# MDR1923VK014 register map
Vendor: Milandr; Series: ARMCM0; File version: 2.0
CPU: CM0 r0p0, little endian, no MPU, no FPU, 3 interrupt priority bits
Registers are 32-bit, read-write, reset 0x0 unless marked. A register's access mark holds for its fields unless they carry their own. Offsets are from the block's base; [hi:lo] are bit positions; {n}, {i} and the like mark numbered series; 'fields as' and 'values as' point back to an identical list.

## MDR_TIMER1 — TIMER Control
Base 0x4008A000
Same registers: MDR_TIMER2 0x4008B000, MDR_TIMER3 0x4008C000, MDR_TIMER4 0x4008D000, MDR_TIMER5 0x4008E000, MDR_TIMER6 0x4008F000
0x00 CNT — Counter register
  [31:0] Value — Counter Value
0x04 PSG — Presample Gain
  [15:0] Value — Inc CNT by PSG clocks of TIM_CLOCK
0x08 ARR — Counter Period
  [31:0] Value — Counter Value
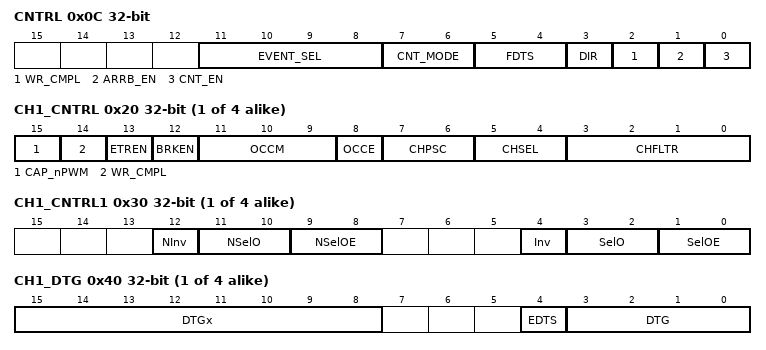
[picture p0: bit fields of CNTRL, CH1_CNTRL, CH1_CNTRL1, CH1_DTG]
0x0C CNTRL — Timer Control
  [11:8] EVENT_SEL — Events for counting
    0=Rise_TIM_CLK (CNT counts from 0 to ARR); 1=CNT_eq_ARR_TIM1 (CNT gets ARR in Timer1); 2=CNT_eq_ARR_TIM2 (CNT gets ARR in Timer2); 3=CNT_eq_ARR_TIM3 (CNT gets ARR in Timer3); {v}=Event_Ch{v-3} (Event in Channel{v-3}) (v=4..7); 8=Rise_ETR (Rise front in ETR pin); 9=Fall_ETR (Fall front in ETR pin); 10=CNT_eq_ARR_TIM4 (CNT gets ARR in Timer4)
  [7:6] CNT_MODE — Counting mode
    0=DIR_TIM_CLK (Count TIM_Clock pulses with DIR direction); 1=UpDown_TIM_CLK (Count TIM_Clock pulses UP and Down); 2=DIR_ExtEvents (Count External Events with DIR direction)
  [5:4] FDTS — Select Data Sampling frequency
    0=TIM_CLK_div1 (TIM_Clock to FDTS scale); 1=TIM_CLK_div2 (TIM_Clock to FDTS scale); 2=TIM_CLK_div4 (TIM_Clock to FDTS scale); 3=TIM_CLK_div8 (TIM_Clock to FDTS scale)
  [3] DIR — Count Direction
    0=UP (CNT counts from 0 to ARR); 1=DOWN (CNT counts from ARR to 0)
  [2] WR_CMPL — Can write to CNT, ARR, PSG
    0=Ready to write; 1=BUSY (Writing not completed)
  [1] ARRB_EN — ARR update mode
    0=Immediately update; 1=OnCompleted (Update ARR when active period of CNT finished)
  [0] CNT_EN — Timer Enable
    0=Off (Disabled); 1=On (Enabled)
{0xC+4i} CCR{i} (i=1..4) — CNT Compare Register
  [31:0] Value — Captured or PWM Value
{0x1C+4i} CH{i}_CNTRL (i=1..4) — Capture and PWM Channel Control
  [15] CAP_nPWM — CAP or PWM Mode
    0=PWM (PWM output); 1=CAPTURE (Capture input signal)
  [14] WR_CMPL — Can write to CCRx
    0=Ready to write; 1=BUSY (Writing not completed)
  [13] ETREN — Clear Ref by BRK
    0=Off (Disabled); 1=On (Enabled)
  [12] BRKEN — Clear Ref by BRK
    0=Off (Disabled); 1=On (Enabled)
  [11:9] OCCM — PWM Generate modes
    0=Ref_0 (Ref signal for output); 1=Ref_1_eqCCRx (Ref signal for output); 2=Ref_0_eqCCRx (Ref signal for output); 3=Ref_sw_eqCCRx (Ref signal for output); 4=Ref0 (Ref signal for output); 5=Ref_1 (Ref signal for output); 6=Ref_nDir_inCCRs (Ref signal for output); 7=Ref_Dir_inCCRs (Ref signal for output)
  [8] OCCE — ETR pin Enable
    0=Off (Disabled); 1=On (Enabled)
  [7:6] CHPSC — Capture event decimation
    0=EveryEvent (Pass event for capture); 1=Events_div2 (Pass event for capture); 2=Events_div4 (Pass event for capture); 3=Events_div8 (Pass event for capture)
  [5:4] CHSEL — Event to capture in CCR
    0=Rise_Pin (Capture Event Select); 1=Fall_Pin (Capture Event Select); 2=Rise_NextCH (Capture Event Select); 3=Rise_NextNextCH (Capture Event Select)
  [3:0] CHFLTR — Front hold to set Event
    0=TIM_CLK (Filter Value); 1=2_TIM_CLK (Filter Value); 2=4_TIM_CLK (Filter Value); 3=8_TIM_CLK (Filter Value); 4=6_FDTS_div2 (Filter Value); 5=8_FDTS_div2 (Filter Value); 6=6_FDTS_div4 (Filter Value); 7=8_FDTS_div4 (Filter Value); 8=6_FDTS_div8 (Filter Value); 9=8_FDTS_div8 (Filter Value); 10=5_FDTS_div16 (Filter Value); 11=6_FDTS_div16 (Filter Value); 12=8_FDTS_div16 (Filter Value); 13=5_FDTS_div32 (Filter Value); 14=6_FDTS_div32 (Filter Value); 15=8_FDTS_div32 (Filter Value)
{0x2C+4i} CH{i}_CNTRL1 (i=1..4) — PWM Driver Control
  [12] NInv — Invert Output Signal
    0=Off (Not Inverted); 1=On (Inverted)
  [11:10] NSelO — Select Output Signal
    0=Low (Outputs const GND); 1=High (Outputs const Ucc); 2=Ref (Ref PWM signal); 3=DTG (DTG PWM signal)
  [9:8] NSelOE — Select Pin Output Enable
    0=IN (Pin IN); 1=OUT (Pin OUT); 2=IO_byRef (Pin IN or OUT by Ref signal); 3=IO_byDTG (Pin IN or OUT by DTG signal)
  [4] Inv — Invert Output Signal
    0=Off (Not Inverted); 1=On (Inverted)
  [3:2] SelO — Select Output Signal
    values as NSelO
  [1:0] SelOE — Select Pin Output Enable
    values as NSelOE
{0x3C+4i} CH{i}_DTG (i=1..4) — Dead Time Generator
  [15:8] DTGx — DTGx scale, Delay = DTGx*(DTG + 1)
  [4] EDTS — DTG Clock Select
    0=TIM_Clock (Pin IN); 1=FDTS (Pin OUT)
  [3:0] DTG — DTG Prescaller
    0=Prescaler DTG; 1=Prescaler DTG; {v}=x{v} (Prescaler DTG) (v=2..9); 10=Prescaler DTG; 11=Prescaler DTG; {v}=x{v} (Prescaler DTG) (v=12..15)
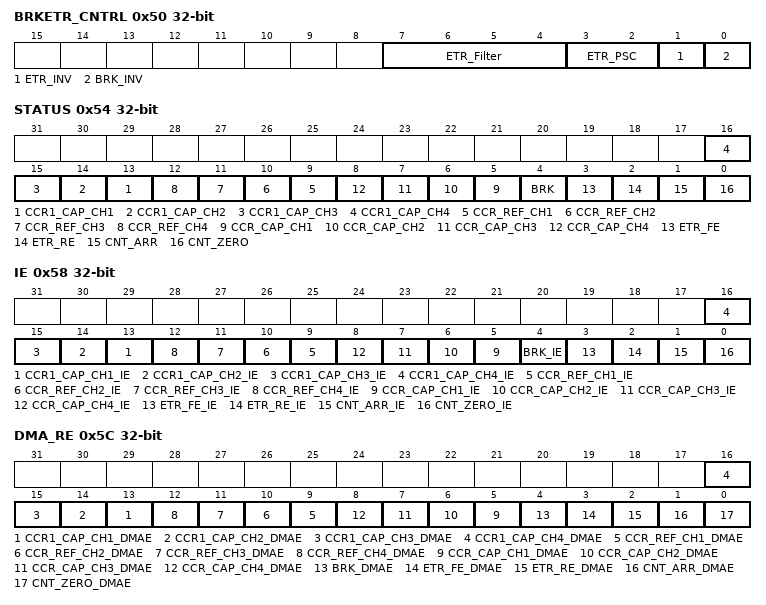
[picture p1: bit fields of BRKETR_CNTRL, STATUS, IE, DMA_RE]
0x50 BRKETR_CNTRL — Break and External Count Control
  [7:4] ETR_Filter — External Count Signal Filter
    values as CH1_CNTRL.CHFLTR
  [3:2] ETR_PSC — External Count Div
    0=div1 (No prescaler); 1=div2 (Reduce freq by 2); 2=div4 (Reduce freq by 4); 3=div8 (Reduce freq by 8)
  [1] ETR_INV — Invert External Count Signal
    0=Normal (Signal Not Inverted); 1=Invert (Signal Inverted)
  [0] BRK_INV — Invert Break Signal
    0=Normal (Signal Not Inverted); 1=Invert (Signal Inverted)
0x54 STATUS
  [all] fields
    0=Off (Inactive); 1=On (Active)
  [n+12] CCR1_CAP_CH{n} (n=1..4) — Captured to CCR1
  [n+8] CCR_REF_CH{n} (n=1..4) — PWM Rise Front
  [n+4] CCR_CAP_CH{n} (n=1..4) — Captured to CCR
  [4] BRK — BRK High Level
  [3] ETR_FE — ETR Fall Front
  [2] ETR_RE — ETR Rise Front
  [1] CNT_ARR — CNT eq ARR
  [0] CNT_ZERO
0x58 IE — IRQ Enable
  [all] fields
    0=Off (Disable); 1=On (ENable)
  [n+12] CCR1_CAP_CH{n}_IE (n=1..4) — Captured to CCR1
  [n+8] CCR_REF_CH{n}_IE (n=1..4) — PWM Rise Front
  [n+4] CCR_CAP_CH{n}_IE (n=1..4) — Captured to CCR
  [4] BRK_IE — BRK High Level
  [3] ETR_FE_IE — ETR Fall Front
  [2] ETR_RE_IE — ETR Rise Front
  [1] CNT_ARR_IE — CNT eq ARR
  [0] CNT_ZERO_IE — CNT Zero
0x5C DMA_RE — DMA Request Enable for TIMx_DMA_REQ
  [all] fields
    0=Off (Inactive); 1=On (Active)
  [n+12] CCR1_CAP_CH{n}_DMAE (n=1..4) — Captured to CCR1
  [n+8] CCR_REF_CH{n}_DMAE (n=1..4) — PWM Rise Front
  [n+4] CCR_CAP_CH{n}_DMAE (n=1..4) — Captured to CCR
  [4] BRK_DMAE — BRK High Level
  [3] ETR_FE_DMAE — ETR Fall Front
  [2] ETR_RE_DMAE — ETR Rise Front
  [1] CNT_ARR_DMAE — CNT eq ARR
  [0] CNT_ZERO_DMAE — CNT Zero
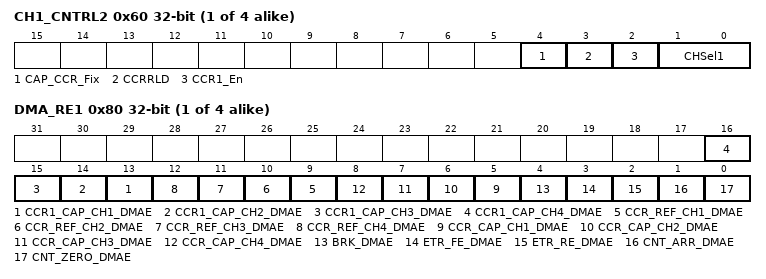
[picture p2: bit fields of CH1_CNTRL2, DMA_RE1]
{0x5C+4i} CH{i}_CNTRL2 (i=1..4) — CCR1 Control
  [4] CAP_CCR_Fix — CAP update CCRs fix
    0=Off (Inactive); 1=On (Active)
  [3] CCRRLD — CCR Reload Mode
    0=Immediately update CCR and CCR1; 1=byPreriodCNT (Update on period completed)
  [2] CCR1_En — Enable CCR1
    0=Off (Disable); 1=On (Enable)
  [1:0] CHSel1 — Event to capture in CCR1
    0=Rise_Pin (Capture Event Select); 1=Fall_Pin (Capture Event Select); 2=Fall_NextCH (Capture Event Select); 3=Fall_NextNextCH (Capture Event Select)
0x70 CCR11 — CNT Compare Register
  [31:0] Value — Captured or PWM Value
0x74 CCR21 — CNT Compare Register
  [31:0] Value — Captured or PWM Value
0x78 CCR31 — CNT Compare Register
  [31:0] Value — Captured or PWM Value
0x7C CCR41 — CNT Compare Register
  [31:0] Value — Captured or PWM Value
{0x7C+4i} DMA_RE{i} (i=1..4) — DMA Request Enable for TIMx_DMA_REQ{i}
  fields as DMA_RE
